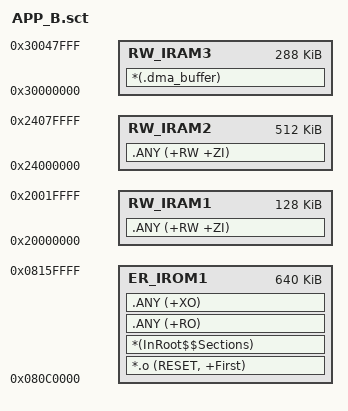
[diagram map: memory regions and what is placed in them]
; *************************************************************
; *** SolarClean Slot B Scatter-Loading Description File      ***
; *************************************************************

LR_IROM1 0x080C0000 0x000A0000  {    ; load region size_region
  ER_IROM1 0x080C0000 0x000A0000  {  ; load address = execution address
   *.o (RESET, +First)
   *(InRoot$$Sections)
   .ANY (+RO)
   .ANY (+XO)
  }
  RW_IRAM3 0x30000000 0x00048000  {
   *(.dma_buffer)
  }
  RW_IRAM1 0x20000000 0x00020000  {  ; RW data
   .ANY (+RW +ZI)
  }
  RW_IRAM2 0x24000000 0x00080000  {
   .ANY (+RW +ZI)
  }
}
